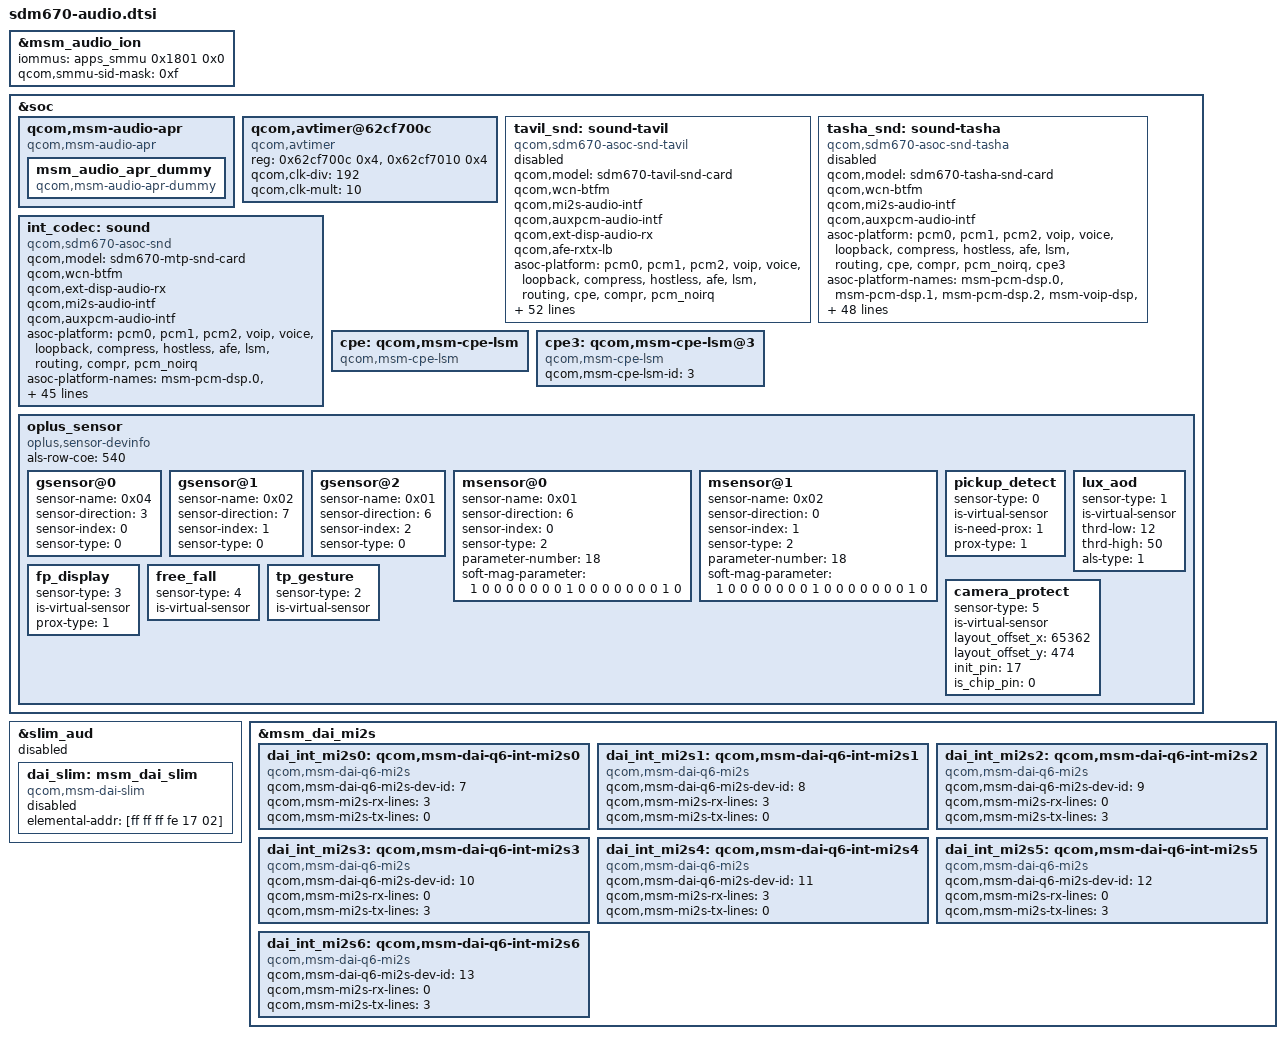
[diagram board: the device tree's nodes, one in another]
/*
 * Copyright (c) 2017-2018, 2020, The Linux Foundation. All rights reserved.
 *
 * This program is free software; you can redistribute it and/or modify
 * it under the terms of the GNU General Public License version 2 and
 * only version 2 as published by the Free Software Foundation.
 *
 * This program is distributed in the hope that it will be useful,
 * but WITHOUT ANY WARRANTY; without even the implied warranty of
 * MERCHANTABILITY or FITNESS FOR A PARTICULAR PURPOSE.  See the
 * GNU General Public License for more details.
 */

#include "msm-audio-lpass.dtsi"

&msm_audio_ion {
	iommus = <&apps_smmu 0x1801 0x0>;
	qcom,smmu-sid-mask = /bits/ 64 <0xf>;
};

&soc {
	qcom,msm-audio-apr {
		compatible = "qcom,msm-audio-apr";
		msm_audio_apr_dummy {
			compatible = "qcom,msm-audio-apr-dummy";
		};
	};

	qcom,avtimer@62cf700c {
		compatible = "qcom,avtimer";
		reg = <0x62cf700c 0x4>,
			<0x62cf7010 0x4>;
		reg-names = "avtimer_lsb_addr", "avtimer_msb_addr";
		qcom,clk-div = <192>;
		qcom,clk-mult = <10>;
	};

	tavil_snd: sound-tavil {
		status = "disabled";
		compatible = "qcom,sdm670-asoc-snd-tavil";
		qcom,model = "sdm670-tavil-snd-card";
		qcom,wcn-btfm;
		qcom,mi2s-audio-intf;
		qcom,auxpcm-audio-intf;
		qcom,ext-disp-audio-rx;
		qcom,afe-rxtx-lb;
		asoc-platform = <&pcm0>, <&pcm1>, <&pcm2>, <&voip>, <&voice>,
			<&loopback>, <&compress>, <&hostless>,
			<&afe>, <&lsm>, <&routing>, <&cpe>, <&compr>,
			<&pcm_noirq>;
		asoc-platform-names = "msm-pcm-dsp.0", "msm-pcm-dsp.1",
			"msm-pcm-dsp.2", "msm-voip-dsp",
			"msm-pcm-voice", "msm-pcm-loopback",
			"msm-compress-dsp", "msm-pcm-hostless",
			"msm-pcm-afe", "msm-lsm-client",
			"msm-pcm-routing", "msm-cpe-lsm",
			"msm-compr-dsp", "msm-pcm-dsp-noirq";
		asoc-cpu = <&dai_dp>, <&dai_mi2s0>, <&dai_mi2s1>,
			<&dai_mi2s2>, <&dai_mi2s3>, <&dai_mi2s4>,
			<&dai_pri_auxpcm>, <&dai_sec_auxpcm>,
			<&dai_tert_auxpcm>, <&dai_quat_auxpcm>,
			<&dai_quin_auxpcm>,
			<&sb_0_rx>, <&sb_0_tx>, <&sb_1_rx>, <&sb_1_tx>,
			<&sb_2_rx>, <&sb_2_tx>, <&sb_3_rx>, <&sb_3_tx>,
			<&sb_4_rx>, <&sb_4_tx>, <&sb_5_rx>, <&sb_5_tx>,
			<&sb_6_rx>, <&sb_7_rx>, <&sb_7_tx>,
			<&sb_8_rx>, <&sb_8_tx>,
			<&proxy_rx>, <&proxy_tx>,
			<&afe_pcm_rx>, <&afe_pcm_tx>, <&afe_proxy_rx>,
			<&afe_proxy_tx>, <&incall_record_rx>,
			<&incall_record_tx>, <&incall_music_rx>,
			<&incall_music_2_rx>,
			<&usb_audio_rx>, <&usb_audio_tx>,
			<&dai_pri_tdm_rx_0>, <&dai_pri_tdm_tx_0>,
			<&dai_sec_tdm_rx_0>, <&dai_sec_tdm_tx_0>,
			<&dai_tert_tdm_rx_0>, <&dai_tert_tdm_tx_0>,
			<&dai_quat_tdm_rx_0>, <&dai_quat_tdm_tx_0>,
			<&dai_quin_tdm_rx_0>, <&dai_quin_tdm_tx_0>,
			<&afe_loopback_tx>;
		asoc-cpu-names = "msm-dai-q6-dp.24608",
			"msm-dai-q6-mi2s.0", "msm-dai-q6-mi2s.1",
			"msm-dai-q6-mi2s.2", "msm-dai-q6-mi2s.3",
			"msm-dai-q6-mi2s.4",
			"msm-dai-q6-auxpcm.1", "msm-dai-q6-auxpcm.2",
			"msm-dai-q6-auxpcm.3", "msm-dai-q6-auxpcm.4",
			"msm-dai-q6-auxpcm.5",
			"msm-dai-q6-dev.16384", "msm-dai-q6-dev.16385",
			"msm-dai-q6-dev.16386", "msm-dai-q6-dev.16387",
			"msm-dai-q6-dev.16388", "msm-dai-q6-dev.16389",
			"msm-dai-q6-dev.16390", "msm-dai-q6-dev.16391",
			"msm-dai-q6-dev.16392", "msm-dai-q6-dev.16393",
			"msm-dai-q6-dev.16394", "msm-dai-q6-dev.16395",
			"msm-dai-q6-dev.16396",
			"msm-dai-q6-dev.16398", "msm-dai-q6-dev.16399",
			"msm-dai-q6-dev.16400", "msm-dai-q6-dev.16401",
			"msm-dai-q6-dev.8194", "msm-dai-q6-dev.8195",
			"msm-dai-q6-dev.224", "msm-dai-q6-dev.225",
			"msm-dai-q6-dev.241", "msm-dai-q6-dev.240",
			"msm-dai-q6-dev.32771", "msm-dai-q6-dev.32772",
			"msm-dai-q6-dev.32773", "msm-dai-q6-dev.32770",
			"msm-dai-q6-dev.28672", "msm-dai-q6-dev.28673",
			"msm-dai-q6-tdm.36864", "msm-dai-q6-tdm.36865",
			"msm-dai-q6-tdm.36880", "msm-dai-q6-tdm.36881",
			"msm-dai-q6-tdm.36896", "msm-dai-q6-tdm.36897",
			"msm-dai-q6-tdm.36912", "msm-dai-q6-tdm.36913",
			"msm-dai-q6-tdm.36928", "msm-dai-q6-tdm.36929",
			"msm-dai-q6-dev.24577";
	};

	tasha_snd: sound-tasha {
		status = "disabled";
		compatible = "qcom,sdm670-asoc-snd-tasha";
		qcom,model = "sdm670-tasha-snd-card";
		qcom,wcn-btfm;
		qcom,mi2s-audio-intf;
		qcom,auxpcm-audio-intf;
		asoc-platform = <&pcm0>, <&pcm1>, <&pcm2>, <&voip>, <&voice>,
			<&loopback>, <&compress>, <&hostless>,
			<&afe>, <&lsm>, <&routing>, <&cpe>, <&compr>,
			<&pcm_noirq>, <&cpe3>;
		asoc-platform-names = "msm-pcm-dsp.0", "msm-pcm-dsp.1",
			"msm-pcm-dsp.2", "msm-voip-dsp",
			"msm-pcm-voice", "msm-pcm-loopback",
			"msm-compress-dsp", "msm-pcm-hostless",
			"msm-pcm-afe", "msm-lsm-client",
			"msm-pcm-routing", "msm-cpe-lsm",
			"msm-compr-dsp", "msm-pcm-dsp-noirq",
			"msm-cpe-lsm.3";
		asoc-cpu = <&dai_mi2s0>, <&dai_mi2s1>,
			<&dai_mi2s2>, <&dai_mi2s3>, <&dai_mi2s4>,
			<&dai_pri_auxpcm>, <&dai_sec_auxpcm>,
			<&dai_tert_auxpcm>, <&dai_quat_auxpcm>,
			<&dai_quin_auxpcm>,
			<&sb_0_rx>, <&sb_0_tx>, <&sb_1_rx>, <&sb_1_tx>,
			<&sb_2_rx>, <&sb_2_tx>, <&sb_3_rx>, <&sb_3_tx>,
			<&sb_4_rx>, <&sb_4_tx>, <&sb_5_rx>, <&sb_5_tx>,
			<&sb_6_rx>, <&sb_7_rx>, <&sb_7_tx>,
			<&sb_8_rx>, <&sb_8_tx>,
			<&afe_pcm_rx>, <&afe_pcm_tx>, <&afe_proxy_rx>,
			<&afe_proxy_tx>, <&incall_record_rx>,
			<&incall_record_tx>, <&incall_music_rx>,
			<&incall_music_2_rx>,
			<&usb_audio_rx>, <&usb_audio_tx>,
			<&dai_pri_tdm_rx_0>, <&dai_pri_tdm_tx_0>,
			<&dai_sec_tdm_rx_0>, <&dai_sec_tdm_tx_0>,
			<&dai_tert_tdm_rx_0>, <&dai_tert_tdm_tx_0>,
			<&dai_quat_tdm_rx_0>, <&dai_quat_tdm_tx_0>,
			<&dai_quin_tdm_rx_0>, <&dai_quin_tdm_tx_0>,
			<&proxy_rx>, <&proxy_tx>;
		asoc-cpu-names = "msm-dai-q6-mi2s.0", "msm-dai-q6-mi2s.1",
			"msm-dai-q6-mi2s.2", "msm-dai-q6-mi2s.3",
			"msm-dai-q6-mi2s.4",
			"msm-dai-q6-auxpcm.1", "msm-dai-q6-auxpcm.2",
			"msm-dai-q6-auxpcm.3", "msm-dai-q6-auxpcm.4",
			"msm-dai-q6-auxpcm.5",
			"msm-dai-q6-dev.16384", "msm-dai-q6-dev.16385",
			"msm-dai-q6-dev.16386", "msm-dai-q6-dev.16387",
			"msm-dai-q6-dev.16388", "msm-dai-q6-dev.16389",
			"msm-dai-q6-dev.16390", "msm-dai-q6-dev.16391",
			"msm-dai-q6-dev.16392", "msm-dai-q6-dev.16393",
			"msm-dai-q6-dev.16394", "msm-dai-q6-dev.16395",
			"msm-dai-q6-dev.16396",
			"msm-dai-q6-dev.16398", "msm-dai-q6-dev.16399",
			"msm-dai-q6-dev.16400", "msm-dai-q6-dev.16401",
			"msm-dai-q6-dev.224", "msm-dai-q6-dev.225",
			"msm-dai-q6-dev.241", "msm-dai-q6-dev.240",
			"msm-dai-q6-dev.32771", "msm-dai-q6-dev.32772",
			"msm-dai-q6-dev.32773", "msm-dai-q6-dev.32770",
			"msm-dai-q6-dev.28672", "msm-dai-q6-dev.28673",
			"msm-dai-q6-tdm.36864", "msm-dai-q6-tdm.36865",
			"msm-dai-q6-tdm.36880", "msm-dai-q6-tdm.36881",
			"msm-dai-q6-tdm.36896", "msm-dai-q6-tdm.36897",
			"msm-dai-q6-tdm.36912", "msm-dai-q6-tdm.36913",
			"msm-dai-q6-tdm.36928", "msm-dai-q6-tdm.36929",
			"msm-dai-q6-dev.8194", "msm-dai-q6-dev.8195";
	};

	int_codec: sound {
		status = "okay";
		compatible = "qcom,sdm670-asoc-snd";
		qcom,model = "sdm670-mtp-snd-card";
		qcom,wcn-btfm;
		qcom,ext-disp-audio-rx;
		qcom,mi2s-audio-intf;
		qcom,auxpcm-audio-intf;
		asoc-platform = <&pcm0>, <&pcm1>, <&pcm2>, <&voip>, <&voice>,
			<&loopback>, <&compress>, <&hostless>,
			<&afe>, <&lsm>, <&routing>, <&compr>,
			<&pcm_noirq>;
		asoc-platform-names = "msm-pcm-dsp.0", "msm-pcm-dsp.1",
			"msm-pcm-dsp.2", "msm-voip-dsp",
			"msm-pcm-voice", "msm-pcm-loopback",
			"msm-compress-dsp", "msm-pcm-hostless",
			"msm-pcm-afe", "msm-lsm-client",
			"msm-pcm-routing", "msm-compr-dsp",
			"msm-pcm-dsp-noirq";
		asoc-cpu = <&dai_dp>, <&dai_mi2s0>, <&dai_mi2s1>,
			<&dai_mi2s2>, <&dai_mi2s3>, <&dai_mi2s4>,
			<&dai_int_mi2s0>, <&dai_int_mi2s1>,
			<&dai_int_mi2s2>, <&dai_int_mi2s3>,
			<&dai_int_mi2s4>, <&dai_int_mi2s5>,
			<&dai_pri_auxpcm>, <&dai_sec_auxpcm>,
			<&dai_tert_auxpcm>, <&dai_quat_auxpcm>,
			<&dai_quin_auxpcm>,
			<&afe_pcm_rx>, <&afe_pcm_tx>, <&afe_proxy_rx>,
			<&afe_proxy_tx>, <&incall_record_rx>,
			<&incall_record_tx>, <&incall_music_rx>,
			<&incall_music_2_rx>, <&sb_7_rx>, <&sb_7_tx>,
			<&sb_8_tx>, <&sb_8_rx>,
			<&usb_audio_rx>, <&usb_audio_tx>,
			<&dai_pri_tdm_rx_0>, <&dai_pri_tdm_tx_0>,
			<&dai_sec_tdm_rx_0>, <&dai_sec_tdm_tx_0>,
			<&dai_tert_tdm_rx_0>, <&dai_tert_tdm_tx_0>,
			<&dai_quat_tdm_rx_0>, <&dai_quat_tdm_tx_0>,
			<&dai_quin_tdm_rx_0>, <&dai_quin_tdm_tx_0>,
			<&proxy_rx>, <&proxy_tx>;
		asoc-cpu-names = "msm-dai-q6-dp.24608",
			"msm-dai-q6-mi2s.0","msm-dai-q6-mi2s.1",
			"msm-dai-q6-mi2s.2", "msm-dai-q6-mi2s.3",
			"msm-dai-q6-mi2s.4",
			"msm-dai-q6-mi2s.7", "msm-dai-q6-mi2s.8",
			"msm-dai-q6-mi2s.9", "msm-dai-q6-mi2s.10",
			"msm-dai-q6-mi2s.11", "msm-dai-q6-mi2s.12",
			"msm-dai-q6-auxpcm.1", "msm-dai-q6-auxpcm.2",
			"msm-dai-q6-auxpcm.3", "msm-dai-q6-auxpcm.4",
			"msm-dai-q6-auxpcm.5",
			"msm-dai-q6-dev.224", "msm-dai-q6-dev.225",
			"msm-dai-q6-dev.241", "msm-dai-q6-dev.240",
			"msm-dai-q6-dev.32771", "msm-dai-q6-dev.32772",
			"msm-dai-q6-dev.32773", "msm-dai-q6-dev.32770",
			"msm-dai-q6-dev.16398", "msm-dai-q6-dev.16399",
			"msm-dai-q6-dev.16401", "msm-dai-q6-dev.16400",
			"msm-dai-q6-dev.28672", "msm-dai-q6-dev.28673",
			"msm-dai-q6-tdm.36864", "msm-dai-q6-tdm.36865",
			"msm-dai-q6-tdm.36880", "msm-dai-q6-tdm.36881",
			"msm-dai-q6-tdm.36896", "msm-dai-q6-tdm.36897",
			"msm-dai-q6-tdm.36912", "msm-dai-q6-tdm.36913",
			"msm-dai-q6-tdm.36928", "msm-dai-q6-tdm.36929",
			"msm-dai-q6-dev.8194", "msm-dai-q6-dev.8195";
	};

	cpe: qcom,msm-cpe-lsm {
		compatible = "qcom,msm-cpe-lsm";
	};

	cpe3: qcom,msm-cpe-lsm@3 {
		compatible = "qcom,msm-cpe-lsm";
		qcom,msm-cpe-lsm-id = <3>;
	};

	//#ifdef OPLUS_FEATURE_SENSOR_SMEM
	//oplus
	/*enum sensor_id { OPPO_ACCEL,OPPO_GYRO,OPPO_MAG,OPPO_LIGHT,OPPO_PROXIMITY,OPPO_SAR,OPPO_CT,OPPO_BAROMETER,SENSORS_NUM};*/
	oplus_sensor {
		compatible = "oplus,sensor-devinfo";
		als-row-coe = <540>;
		/*enum {LSM6DSM = 0x01, BMI160 = 0x02, LSM6DS3 = 0x04, BMI260 = 0x08};*/
		gsensor@0 {
			sensor-name = <0x04>;//LSM6DS3
			sensor-direction = <3>;
			sensor-index = <0>;//source num
			sensor-type = <0>;//OPPO_ACCEL
		};
		gsensor@1 {
			sensor-name = <0x02>;//BMI160
			sensor-direction = <7>;
			sensor-index = <1>;//source num
			sensor-type = <0>;//OPPO_ACCEL
		};
		gsensor@2 {
			sensor-name = <0x01>;//LSM6DSM
			sensor-direction = <6>;
			sensor-index = <2>;//source num
			sensor-type = <0>;//OPPO_ACCEL
		};
		/* enum {AKM0991X = 0x01, MMC5603 = 0x02};*/
		msensor@0 {
			sensor-name = <0x01>;//AKM09918
			sensor-direction = <6>;
			sensor-index = <0>;
			sensor-type = <2>;//OPPO_MAG
			parameter-number= <18>;
			soft-mag-parameter = <1 0 0 0 0 0 0 0 1 0 0 0 0 0 0 0 1 0>; //e00 sign e01 sign...
		};
		/*
		msensor@0 {
			sensor-name = <0x01>;//AKM09918
			sensor-direction = <2>;
			sensor-index = <0>;
			sensor-type = <2>;//OPPO_MAG
			parameter-number= <18>;
			soft-mag-parameter = <1 0 0 0 0 0 0 0 1 0 0 0 0 0 0 0 1 0>; //e00 sign e01 sign...
		};*/
		msensor@1 {
			sensor-name = <0x02>;//MMC5603
			sensor-direction = <0>;
			sensor-index = <1>;
			sensor-type = <2>;//OPPO_MAG
			parameter-number= <18>;
			soft-mag-parameter = <1 0 0 0 0 0 0 0 1 0 0 0 0 0 0 0 1 0>; //e00 sign e01 sign...
		};
		/*enum {STK3A5X=0x01,TCS3701=0x02,TCS3408=0x04,STK3A6X=0x08};*/
		/*enum {NORMAL=0x01,UNDER_LCD=0x02,VIRTUAL_UNDER_LCD=0x03}*/

		/*virtual sensor
		enum sensor_algo_id {
			OPPO_PICKUP_DETECT,
			OPPO_LUX_AOD,
			OPPO_TP_GESTURE,
			OPPO_FP_DISPLAY,
			OPPO_FREE_FALL,
			OPPO_CAMERA_PROTECT,
			SENSOR_ALGO_NUM
		}*/
		pickup_detect {
			sensor-type = <0>; //OPPO_PICKUP_DETECT
			is-virtual-sensor;
			is-need-prox = <1>;
			prox-type = <1>; // 0 - proximity; 1 - proximity_fake
		};
		lux_aod {
			sensor-type = <1>; //OPPO_LUX_AOD
			is-virtual-sensor;
			thrd-low = <12>;
			thrd-high = <50>;
			als-type = <1>; // 1 - ambient_light; 0 - wise_light
		};
		fp_display {
			sensor-type = <3>; //OPPO_FP_DISPLAY
			is-virtual-sensor;
			prox-type = <1>; // 0 - proximity; 1 - proximity_fake
		};
		free_fall {
			sensor-type = <4>; //OPPO_FREE_FALL
			is-virtual-sensor;
		};
		tp_gesture {
			sensor-type = <2>; //OPPO_TP_GESTURE
			is-virtual-sensor;
		};
		camera_protect {
			sensor-type = <5>; //OPPO_CAMERA_PROTECT
			is-virtual-sensor;
			layout_offset_x = <65362>;
			layout_offset_y = <474>;
			init_pin = <17>;
			is_chip_pin = <0>;
		};
	};
	//#endif /*OPLUS_FEATURE_SENSOR_SMEM*/
};

&slim_aud {
	status = "disabled";
	dai_slim: msm_dai_slim {
		status = "disabled";
		compatible = "qcom,msm-dai-slim";
		elemental-addr = [ff ff ff fe 17 02];
	};
};

&msm_dai_mi2s {
	dai_int_mi2s0: qcom,msm-dai-q6-int-mi2s0 {
		compatible = "qcom,msm-dai-q6-mi2s";
		qcom,msm-dai-q6-mi2s-dev-id = <7>;
		qcom,msm-mi2s-rx-lines = <3>;
		qcom,msm-mi2s-tx-lines = <0>;
	};

	dai_int_mi2s1: qcom,msm-dai-q6-int-mi2s1 {
		compatible = "qcom,msm-dai-q6-mi2s";
		qcom,msm-dai-q6-mi2s-dev-id = <8>;
		qcom,msm-mi2s-rx-lines = <3>;
		qcom,msm-mi2s-tx-lines = <0>;
	};

	dai_int_mi2s2: qcom,msm-dai-q6-int-mi2s2 {
		compatible = "qcom,msm-dai-q6-mi2s";
		qcom,msm-dai-q6-mi2s-dev-id = <9>;
		qcom,msm-mi2s-rx-lines = <0>;
		qcom,msm-mi2s-tx-lines = <3>;
	};

	dai_int_mi2s3: qcom,msm-dai-q6-int-mi2s3 {
		compatible = "qcom,msm-dai-q6-mi2s";
		qcom,msm-dai-q6-mi2s-dev-id = <10>;
		qcom,msm-mi2s-rx-lines = <0>;
		qcom,msm-mi2s-tx-lines = <3>;
	};

	dai_int_mi2s4: qcom,msm-dai-q6-int-mi2s4 {
		compatible = "qcom,msm-dai-q6-mi2s";
		qcom,msm-dai-q6-mi2s-dev-id = <11>;
		qcom,msm-mi2s-rx-lines = <3>;
		qcom,msm-mi2s-tx-lines = <0>;
	};

	dai_int_mi2s5: qcom,msm-dai-q6-int-mi2s5 {
		compatible = "qcom,msm-dai-q6-mi2s";
		qcom,msm-dai-q6-mi2s-dev-id = <12>;
		qcom,msm-mi2s-rx-lines = <0>;
		qcom,msm-mi2s-tx-lines = <3>;
	};

	dai_int_mi2s6: qcom,msm-dai-q6-int-mi2s6 {
		compatible = "qcom,msm-dai-q6-mi2s";
		qcom,msm-dai-q6-mi2s-dev-id = <13>;
		qcom,msm-mi2s-rx-lines = <0>;
		qcom,msm-mi2s-tx-lines = <3>;
	};
};
